VERSION "J35_Common"

NS_ :

BS_:

BU_: PCM UNKNOWN

BO_ 316 PCM_0x13C: 8 PCM
 SG_ TORQUE_ESTIMATE : 7|16@0- (1,0) [-32768|32767] "raw"  UNKNOWN
 SG_ TORQUE_TARGET : 23|16@0- (1,0) [-32768|32767] "raw"  UNKNOWN
 SG_ ACCELERATOR_REQUEST : 32|8@1+ (0.39215686274509803,0) [0|100] "%"  UNKNOWN
 SG_ TORQUE_STATE : 40|2@1+ (1,0) [0|3] ""  UNKNOWN
 SG_ RSVD_1 : 42|2@1+ (1,0) [0|3] ""  UNKNOWN
 SG_ UNKNOWN_1 : 44|1@1+ (1,0) [0|1] ""  UNKNOWN
 SG_ FRAME_1AA_WINDOW_LATCH : 45|1@1+ (1,0) [0|1] ""  UNKNOWN
 SG_ START_PHASE_LATCH : 46|1@1+ (1,0) [0|1] ""  UNKNOWN
 SG_ DTC_STATUS_7_LATCH : 47|1@1+ (1,0) [0|1] ""  UNKNOWN
 SG_ RSVD_3 : 48|2@1+ (1,0) [0|3] ""  UNKNOWN
 SG_ CLUTCH_ENGAGEMENT_INFORMATION_CRUISE_CONTROL : 50|1@1+ (1,0) [0|1] ""  UNKNOWN
 SG_ CONTROL_GUARD : 51|1@1+ (1,0) [0|1] ""  UNKNOWN
 SG_ RSVD_4 : 52|4@1+ (1,0) [0|15] ""  UNKNOWN
 SG_ CHECKSUM : 56|4@1+ (1,0) [0|15] ""  UNKNOWN
 SG_ COUNTER : 60|2@1+ (1,0) [0|3] ""  UNKNOWN
 SG_ RSVD_5 : 62|1@1+ (1,0) [0|1] ""  UNKNOWN
 SG_ FRAME_1AA_INVALID_OR_FALLBACK_STATE_TBD : 63|1@1+ (1,0) [0|1] ""  UNKNOWN
VAL_ 316 CLUTCH_ENGAGEMENT_INFORMATION_CRUISE_CONTROL 0 "ON" 1 "OFF" ;
VAL_ 316 TORQUE_STATE 0 "NORMAL" 1 "VSA_CONTROL_CANDIDATE" 2 "FUEL_CUT" 3 "UNKNOWN" ;

CM_ SG_ 316 CLUTCH_ENGAGEMENT_INFORMATION_CRUISE_CONTROL "CANFI: Clutch Engagement Information (Cruise Control)";
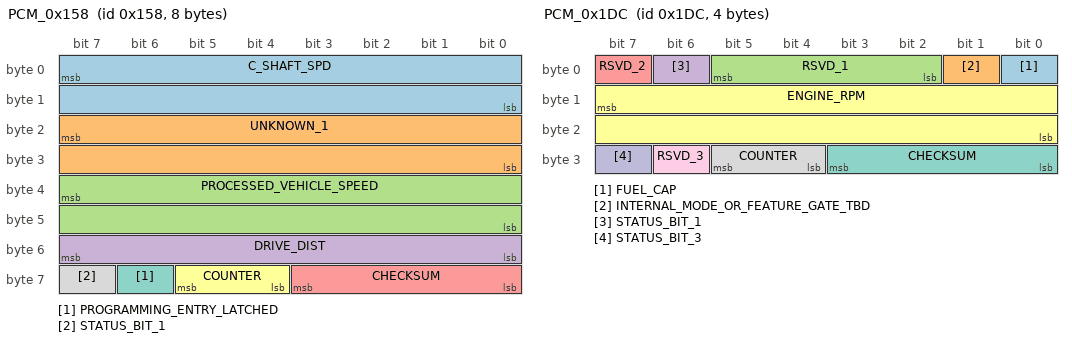
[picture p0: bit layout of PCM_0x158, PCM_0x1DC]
BO_ 344 PCM_0x158: 8 PCM
 SG_ C_SHAFT_SPD : 7|16@0+ (0.01,0) [0|655.35] ""  UNKNOWN
 SG_ UNKNOWN_1 : 23|16@0+ (1,0) [0|65535] "raw"  UNKNOWN
 SG_ PROCESSED_VEHICLE_SPEED : 39|16@0+ (0.01,0) [0|655.35] ""  UNKNOWN
 SG_ DRIVE_DIST : 48|8@1+ (1,0) [0|255] "raw"  UNKNOWN
 SG_ CHECKSUM : 56|4@1+ (1,0) [0|15] ""  UNKNOWN
 SG_ COUNTER : 60|2@1+ (1,0) [0|3] ""  UNKNOWN
 SG_ PROGRAMMING_ENTRY_LATCHED : 62|1@1+ (1,0) [0|1] ""  UNKNOWN
 SG_ STATUS_BIT_1 : 63|1@1+ (1,0) [0|1] ""  UNKNOWN

CM_ SG_ 344 DRIVE_DIST "CANFI: Drive Dist";
BO_ 380 PCM_0x17C: 8 PCM
 SG_ ACCELERATOR_PEDAL_POSITION : 0|8@1+ (0.39215686274509803,0) [0|100] "%"  UNKNOWN
 SG_ THROTTLE_ABOVE_IDLE : 8|8@1+ (0.4,0) [0|102] "deg"  UNKNOWN
 SG_ ENGINE_SPEED : 23|16@0+ (1,0) [0|65535] "rpm"  UNKNOWN
 SG_ BRAKE_SWITCH : 32|1@1+ (1,0) [0|1] ""  UNKNOWN
 SG_ CRUISE_CANCEL_EVENT : 33|1@1+ (1,0) [0|1] ""  UNKNOWN
 SG_ CRUISE_FAULT_SPEED_INHIBIT : 34|1@1+ (1,0) [0|1] ""  UNKNOWN
 SG_ CRUISE_ENGAGED : 35|1@1+ (1,0) [0|1] ""  UNKNOWN
 SG_ MIL : 36|1@1+ (1,0) [0|1] ""  UNKNOWN
 SG_ MIL_STATUS : 37|1@1+ (1,0) [0|1] ""  UNKNOWN
 SG_ CRUISE_INDICATOR : 38|1@1+ (1,0) [0|1] ""  UNKNOWN
 SG_ GAS_PEDAL_PRESSED : 39|1@1+ (1,0) [0|1] ""  UNKNOWN
 SG_ RSVD_1 : 40|2@1+ (1,0) [0|3] ""  UNKNOWN
 SG_ ACCEL_PEDAL_FAULT : 42|1@1+ (1,0) [0|1] ""  UNKNOWN
 SG_ RSVD_2 : 43|5@1+ (1,0) [0|31] ""  UNKNOWN
 SG_ RSVD_3 : 48|5@1+ (1,0) [0|31] ""  UNKNOWN
 SG_ CRUISE_BRAKE_SW_IDLE_STOP_SW : 53|1@1+ (1,0) [0|1] ""  UNKNOWN
 SG_ CRUISE_TRANS_REQUEST_WIRE : 54|2@1+ (1,0) [0|3] ""  UNKNOWN
 SG_ CHECKSUM : 56|4@1+ (1,0) [0|15] ""  UNKNOWN
 SG_ COUNTER : 60|2@1+ (1,0) [0|3] ""  UNKNOWN
 SG_ RSVD_4 : 62|1@1+ (1,0) [0|1] ""  UNKNOWN
 SG_ DTC_GROUP_WARNING_REQUESTED : 63|1@1+ (1,0) [0|1] ""  UNKNOWN
VAL_ 380 CRUISE_BRAKE_SW_IDLE_STOP_SW 0 "CLOSE" 1 "OPEN" ;
VAL_ 380 CRUISE_INDICATOR 0 "OFF" 1 "ON" ;
VAL_ 380 MIL_STATUS 0 "OFF" 1 "ON" ;
VAL_ 380 MIL 0 "OFF" 1 "ON" ;
VAL_ 380 BRAKE_SWITCH 0 "OFF" 1 "ON" ;

CM_ SG_ 380 ENGINE_SPEED "CANFI: Engine Speed";
CM_ SG_ 380 BRAKE_SWITCH "CANFI: Brake Switch";
CM_ SG_ 380 MIL "CANFI: MIL";
CM_ SG_ 380 MIL_STATUS "CANFI: MIL Status";
CM_ SG_ 380 CRUISE_INDICATOR "CANFI: Cruise Indicator";
CM_ SG_ 380 CRUISE_BRAKE_SW_IDLE_STOP_SW "CANFI: Cruise Brake Sw/Idle Stop Sw";
BO_ 476 PCM_0x1DC: 4 PCM
 SG_ FUEL_CAP : 0|1@1+ (1,0) [0|1] ""  UNKNOWN
 SG_ INTERNAL_MODE_OR_FEATURE_GATE_TBD : 1|1@1+ (1,0) [0|1] ""  UNKNOWN
 SG_ RSVD_1 : 2|4@1+ (1,0) [0|15] ""  UNKNOWN
 SG_ STATUS_BIT_1 : 6|1@1+ (1,0) [0|1] ""  UNKNOWN
 SG_ RSVD_2 : 7|1@1+ (1,0) [0|1] ""  UNKNOWN
 SG_ ENGINE_RPM : 15|16@0+ (1,0) [0|65535] "rpm"  UNKNOWN
 SG_ CHECKSUM : 24|4@1+ (1,0) [0|15] ""  UNKNOWN
 SG_ COUNTER : 28|2@1+ (1,0) [0|3] ""  UNKNOWN
 SG_ RSVD_3 : 30|1@1+ (1,0) [0|1] ""  UNKNOWN
 SG_ STATUS_BIT_3 : 31|1@1+ (1,0) [0|1] ""  UNKNOWN
VAL_ 476 FUEL_CAP 0 "CLOSE" 1 "OPEN" ;

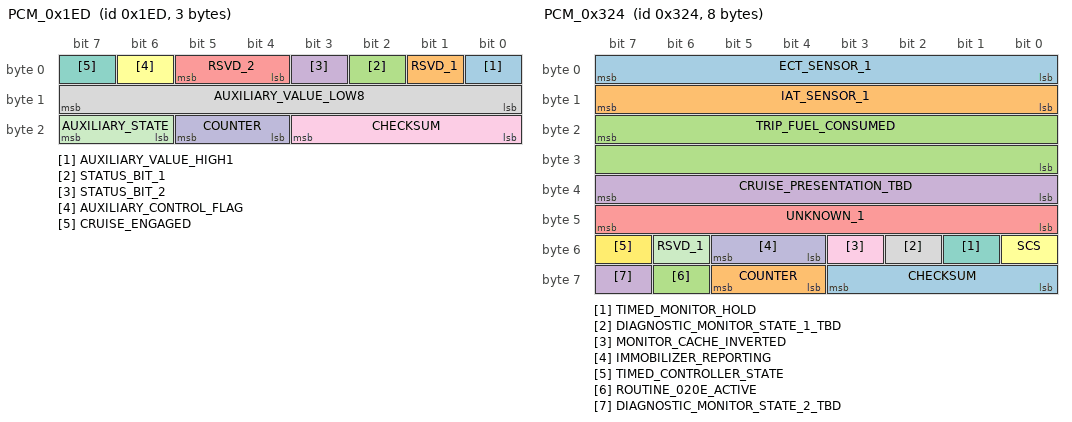
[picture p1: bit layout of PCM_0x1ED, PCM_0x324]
BO_ 493 PCM_0x1ED: 3 PCM
 SG_ AUXILIARY_VALUE_HIGH1 : 0|1@1+ (1,0) [0|1] ""  UNKNOWN
 SG_ RSVD_1 : 1|1@1+ (1,0) [0|1] ""  UNKNOWN
 SG_ STATUS_BIT_1 : 2|1@1+ (1,0) [0|1] ""  UNKNOWN
 SG_ STATUS_BIT_2 : 3|1@1+ (1,0) [0|1] ""  UNKNOWN
 SG_ RSVD_2 : 4|2@1+ (1,0) [0|3] ""  UNKNOWN
 SG_ AUXILIARY_CONTROL_FLAG : 6|1@1+ (1,0) [0|1] ""  UNKNOWN
 SG_ CRUISE_ENGAGED : 7|1@1+ (1,0) [0|1] ""  UNKNOWN
 SG_ AUXILIARY_VALUE_LOW8 : 8|8@1+ (1,0) [0|255] ""  UNKNOWN
 SG_ CHECKSUM : 16|4@1+ (1,0) [0|15] ""  UNKNOWN
 SG_ COUNTER : 20|2@1+ (1,0) [0|3] ""  UNKNOWN
 SG_ AUXILIARY_STATE : 22|2@1+ (1,0) [0|3] ""  UNKNOWN

BO_ 800 PCM_0x320: 8 PCM
 SG_ RSVD_1 : 0|6@1+ (1,0) [0|63] ""  UNKNOWN
 SG_ ENGINE_STATE_TBD : 6|2@1+ (1,0) [0|3] ""  UNKNOWN
 SG_ STATUS_BIT_1 : 8|1@1+ (1,0) [0|1] ""  UNKNOWN
 SG_ STATUS_BIT_2 : 9|1@1+ (1,0) [0|1] ""  UNKNOWN
 SG_ RSVD_2 : 10|4@1+ (1,0) [0|15] ""  UNKNOWN
 SG_ STATUS_BIT_3 : 14|1@1+ (1,0) [0|1] ""  UNKNOWN
 SG_ RSVD_3 : 15|1@1+ (1,0) [0|1] ""  UNKNOWN
 SG_ UNKNOWN_1 : 16|3@1+ (1,0) [0|7] ""  UNKNOWN
 SG_ UNKNOWN_4 : 19|3@1+ (1,0) [0|7] ""  UNKNOWN
 SG_ STATUS_BIT_4 : 22|1@1+ (1,0) [0|1] ""  UNKNOWN
 SG_ STATUS_BIT_9_TBD : 23|1@1+ (1,0) [0|1] ""  UNKNOWN
 SG_ RSVD_4 : 24|8@1+ (1,0) [0|255] ""  UNKNOWN
 SG_ RSVD_5 : 32|7@1+ (1,0) [0|127] ""  UNKNOWN
 SG_ STATUS_BIT_5 : 39|1@1+ (1,0) [0|1] ""  UNKNOWN
 SG_ UNKNOWN_2 : 40|3@1+ (1,0) [0|7] ""  UNKNOWN
 SG_ UNKNOWN_3 : 43|3@1+ (1,0) [0|7] ""  UNKNOWN
 SG_ UNKNOWN_5 : 46|2@1+ (1,0) [0|3] ""  UNKNOWN
 SG_ STATUS_BIT_6 : 48|1@1+ (1,0) [0|1] ""  UNKNOWN
 SG_ RSVD_6 : 49|2@1+ (1,0) [0|3] ""  UNKNOWN
 SG_ STATUS_BIT_7 : 51|1@1+ (1,0) [0|1] ""  UNKNOWN
 SG_ RSVD_7 : 52|4@1+ (1,0) [0|15] ""  UNKNOWN
 SG_ CHECKSUM : 56|4@1+ (1,0) [0|15] ""  UNKNOWN
 SG_ COUNTER : 60|2@1+ (1,0) [0|3] ""  UNKNOWN
 SG_ STATUS_BIT_8 : 62|1@1+ (1,0) [0|1] ""  UNKNOWN
 SG_ STATUS_BIT_9 : 63|1@1+ (1,0) [0|1] ""  UNKNOWN

BO_ 804 PCM_0x324: 8 PCM
 SG_ ECT_SENSOR_1 : 0|8@1+ (1,-40) [-40|215] "degC"  UNKNOWN
 SG_ IAT_SENSOR_1 : 8|8@1+ (1,-40) [-40|215] "degC"  UNKNOWN
 SG_ TRIP_FUEL_CONSUMED : 23|16@0+ (1,0) [0|65535] ""  UNKNOWN
 SG_ CRUISE_PRESENTATION_TBD : 32|8@1+ (1,0) [0|255] "raw"  UNKNOWN
 SG_ UNKNOWN_1 : 40|8@1- (1,0) [-128|127] "raw"  UNKNOWN
 SG_ SCS : 48|1@1+ (1,0) [0|1] ""  UNKNOWN
 SG_ TIMED_MONITOR_HOLD : 49|1@1+ (1,0) [0|1] ""  UNKNOWN
 SG_ DIAGNOSTIC_MONITOR_STATE_1_TBD : 50|1@1+ (1,0) [0|1] ""  UNKNOWN
 SG_ MONITOR_CACHE_INVERTED : 51|1@1+ (1,0) [0|1] ""  UNKNOWN
 SG_ IMMOBILIZER_REPORTING : 52|2@1+ (1,0) [0|3] ""  UNKNOWN
 SG_ RSVD_1 : 54|1@1+ (1,0) [0|1] ""  UNKNOWN
 SG_ TIMED_CONTROLLER_STATE : 55|1@1+ (1,0) [0|1] ""  UNKNOWN
 SG_ CHECKSUM : 56|4@1+ (1,0) [0|15] ""  UNKNOWN
 SG_ COUNTER : 60|2@1+ (1,0) [0|3] ""  UNKNOWN
 SG_ ROUTINE_020E_ACTIVE : 62|1@1+ (1,0) [0|1] ""  UNKNOWN
 SG_ DIAGNOSTIC_MONITOR_STATE_2_TBD : 63|1@1+ (1,0) [0|1] ""  UNKNOWN
VAL_ 804 IMMOBILIZER_REPORTING 0 "COMPLETE_ACCEPTED" 1 "INCOMPLETE" 2 "COMPLETE_NOT_ACCEPTED" ;
VAL_ 804 SCS 0 "OPEN" 1 "SHORT" ;
VAL_ 804 IAT_SENSOR_1 255 "INVALID" ;
VAL_ 804 ECT_SENSOR_1 255 "INVALID" ;

CM_ SG_ 804 SCS "CANFI: SCS";
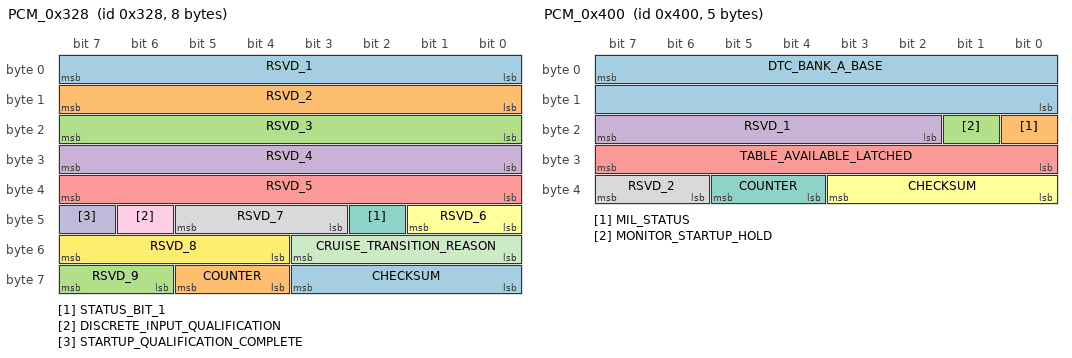
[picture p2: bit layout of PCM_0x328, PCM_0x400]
BO_ 808 PCM_0x328: 8 PCM
 SG_ RSVD_1 : 0|8@1+ (1,0) [0|255] ""  UNKNOWN
 SG_ RSVD_2 : 8|8@1+ (1,0) [0|255] ""  UNKNOWN
 SG_ RSVD_3 : 16|8@1+ (1,0) [0|255] ""  UNKNOWN
 SG_ RSVD_4 : 24|8@1+ (1,0) [0|255] ""  UNKNOWN
 SG_ RSVD_5 : 32|8@1+ (1,0) [0|255] ""  UNKNOWN
 SG_ RSVD_6 : 40|2@1+ (1,0) [0|3] ""  UNKNOWN
 SG_ STATUS_BIT_1 : 42|1@1+ (1,0) [0|1] ""  UNKNOWN
 SG_ RSVD_7 : 43|3@1+ (1,0) [0|7] ""  UNKNOWN
 SG_ DISCRETE_INPUT_QUALIFICATION : 46|1@1+ (1,0) [0|1] ""  UNKNOWN
 SG_ STARTUP_QUALIFICATION_COMPLETE : 47|1@1+ (1,0) [0|1] ""  UNKNOWN
 SG_ CRUISE_TRANSITION_REASON : 48|4@1+ (1,0) [0|15] ""  UNKNOWN
 SG_ RSVD_8 : 52|4@1+ (1,0) [0|15] ""  UNKNOWN
 SG_ CHECKSUM : 56|4@1+ (1,0) [0|15] ""  UNKNOWN
 SG_ COUNTER : 60|2@1+ (1,0) [0|3] ""  UNKNOWN
 SG_ RSVD_9 : 62|2@1+ (1,0) [0|3] ""  UNKNOWN

BO_ 1024 PCM_0x400: 5 PCM
 SG_ DTC_BANK_A_BASE : 7|16@0+ (1,0) [0|65535] ""  UNKNOWN
 SG_ MIL_STATUS : 16|1@1+ (1,0) [0|1] ""  UNKNOWN
 SG_ MONITOR_STARTUP_HOLD : 17|1@1+ (1,0) [0|1] ""  UNKNOWN
 SG_ RSVD_1 : 18|6@1+ (1,0) [0|63] ""  UNKNOWN
 SG_ TABLE_AVAILABLE_LATCHED : 24|8@1+ (1,0) [0|255] ""  UNKNOWN
 SG_ CHECKSUM : 32|4@1+ (1,0) [0|15] ""  UNKNOWN
 SG_ COUNTER : 36|2@1+ (1,0) [0|3] ""  UNKNOWN
 SG_ RSVD_2 : 38|2@1+ (1,0) [0|3] ""  UNKNOWN
VAL_ 1024 MIL_STATUS 0 "OFF" 1 "ON" ;

CM_ SG_ 1024 MIL_STATUS "CANFI: MIL Status";
BO_ 1036 PCM_0x40C: 8 PCM
 SG_ MULTIPLEX_PAGE M : 0|4@1+ (1,0) [0|15] ""  UNKNOWN
 SG_ MULTIPLEX_GROUP : 4|2@1+ (1,0) [0|3] ""  UNKNOWN
 SG_ DIAGNOSTIC_EVENT_STATE : 6|2@1+ (1,0) [0|3] ""  UNKNOWN
 SG_ RSVD_1 m0 : 8|8@1+ (1,0) [0|255] ""  UNKNOWN
 SG_ P01_VIN_CHARACTER_1_B1 m1 : 8|8@1+ (1,0) [0|255] ""  UNKNOWN
 SG_ P02_VIN_CHARACTER_7_B1 m2 : 8|8@1+ (1,0) [0|255] ""  UNKNOWN
 SG_ P03_VIN_CHARACTER_13_B1 m3 : 8|8@1+ (1,0) [0|255] ""  UNKNOWN
 SG_ P04_VARIANT_CONFIG_BYTE_1_B1 m4 : 8|8@1+ (1,0) [0|255] ""  UNKNOWN
 SG_ P05_ENGINE_SPEED m5 : 15|16@0+ (0.25,0) [0|16383.75] "rpm"  UNKNOWN
 SG_ P06_IAT_SENSOR_VOLTAGE_B1 m6 : 8|8@1+ (0.0196078431372549,0) [0|5] "V"  UNKNOWN
 SG_ P07_VEHICLE_SPEED_B1 m7 : 8|8@1+ (1,0) [0|255] "km/h"  UNKNOWN
 SG_ P08_APP_SENSOR m8 : 15|16@0+ (0.005,0) [0|327.675] "%"  UNKNOWN
 SG_ P09_TARGET_TH_VLV m9 : 15|16@0+ (0.005,0) [0|327.675] "deg"  UNKNOWN
 SG_ P0A_AF_SENSOR_B1 m10 : 15|16@0+ (1,0) [0|65535] ""  UNKNOWN
 SG_ UNKNOWN_1 m11 : 8|8@1+ (1,0) [0|255] ""  UNKNOWN
 SG_ P0C_AF_FB_ST_FUEL_TRIM_B2 m12 : 8|8@1+ (0.0078125,0) [0|1.9921875] "ratio"  UNKNOWN
 SG_ P0D_EGR_VALVE_POSITION_SENSOR_EGR_VLS m13 : 8|8@1+ (1,0) [0|255] ""  UNKNOWN
 SG_ P0E_MASS_AIR_FLOW m14 : 15|16@0+ (0.01,0) [0|655.35] "g/s"  UNKNOWN
 SG_ P0F_FUEL_TANK_LEVEL_INPUT_B1 m15 : 8|8@1+ (0.39215686274509803,0) [0|100] "%"  UNKNOWN
 SG_ P00_DIAGNOSTIC_EVENT_CACHE_WORD m0 : 23|16@0+ (1,0) [0|65535] ""  UNKNOWN
 SG_ P01_VIN_CHARACTER_2_B2 m1 : 16|8@1+ (1,0) [0|255] ""  UNKNOWN
 SG_ P02_VIN_CHARACTER_8_B2 m2 : 16|8@1+ (1,0) [0|255] ""  UNKNOWN
 SG_ P03_VIN_CHARACTER_14_B2 m3 : 16|8@1+ (1,0) [0|255] ""  UNKNOWN
 SG_ P04_VARIANT_CONFIG_BYTE_2_B2 m4 : 16|8@1+ (1,0) [0|255] ""  UNKNOWN
 SG_ P06_INTAKE_AIR_TEMPERATURE_B2 m6 : 16|8@1+ (1,-40) [-40|215] "degC"  UNKNOWN
 SG_ P07_CALCULATED_ENGINE_LOAD_B2 m7 : 16|8@1+ (0.39215686274509803,0) [0|100] "%"  UNKNOWN
 SG_ P0B_HO2S_S2_B1 m11 : 16|8@1+ (0.0196078431372549,0) [0|5] "V"  UNKNOWN
 SG_ P0C_AF_FB_AVE_LT_FUEL_TRIM_B2 m12 : 16|8@1+ (0.0078125,0) [0|1.9921875] "ratio"  UNKNOWN
 SG_ RSVD_2 m13 : 16|8@1+ (1,0) [0|255] ""  UNKNOWN
 SG_ RSVD_3 m15 : 16|8@1+ (1,0) [0|255] ""  UNKNOWN
 SG_ P01_VIN_CHARACTER_3_B3 m1 : 24|8@1+ (1,0) [0|255] ""  UNKNOWN
 SG_ P02_VIN_CHARACTER_9_B3 m2 : 24|8@1+ (1,0) [0|255] ""  UNKNOWN
 SG_ P03_VIN_CHARACTER_15_B3 m3 : 24|8@1+ (1,0) [0|255] ""  UNKNOWN
 SG_ P04_VARIANT_CONFIG_BYTE_3_B3 m4 : 24|8@1+ (1,0) [0|255] ""  UNKNOWN
 SG_ P05_THROTTLE_POSITION_B3 m5 : 24|8@1+ (0.39215686274509803,0) [0|100] "%"  UNKNOWN
 SG_ P06_MAP_SENSOR_VOLTAGE_B3 m6 : 24|8@1+ (0.0196078431372549,0) [0|5] "V"  UNKNOWN
 SG_ P07_SPARK_ADVANCE m7 : 24|8@1+ (0.5,-64) [-64|63.5] "deg"  UNKNOWN
 SG_ P08_TP_SENSOR_1 m8 : 24|8@1+ (0.0196078431372549,0) [0|5] "V"  UNKNOWN
 SG_ UNKNOWN_2 m9 : 24|8@1+ (1,0) [0|255] ""  UNKNOWN
 SG_ P0A_AF_LAMBDA_B1 m10 : 31|16@0+ (3.0517578125e-05,0) [0|1.999969482421875] "ratio"  UNKNOWN
 SG_ P0B_AF_SENSOR_B2 m11 : 31|16@0+ (1,0) [0|65535] ""  UNKNOWN
 SG_ UNKNOWN_3 m12 : 24|8@1+ (1,0) [0|255] ""  UNKNOWN
 SG_ RSVD_4 m13 : 24|8@1+ (1,0) [0|255] ""  UNKNOWN
 SG_ RSVD_5 m14 : 24|8@1+ (1,0) [0|255] ""  UNKNOWN
 SG_ RSVD_6 m15 : 24|8@1+ (1,0) [0|255] ""  UNKNOWN
 SG_ UNKNOWN_4 m0 : 32|8@1+ (1,0) [0|255] ""  UNKNOWN
 SG_ P01_VIN_CHARACTER_4_B4 m1 : 32|8@1+ (1,0) [0|255] ""  UNKNOWN
 SG_ P02_VIN_CHARACTER_10_B4 m2 : 32|8@1+ (1,0) [0|255] ""  UNKNOWN
 SG_ P03_VIN_CHARACTER_16_B4 m3 : 32|8@1+ (1,0) [0|255] ""  UNKNOWN
 SG_ P04_VARIANT_CONFIG_BYTE_4_B4 m4 : 32|8@1+ (1,0) [0|255] ""  UNKNOWN
 SG_ P05_RELATIVE_THROTTLE_POSITION_B4 m5 : 32|8@1+ (0.39215686274509803,0) [0|100] "%"  UNKNOWN
 SG_ P06_MANIFOLD_ABSOLUTE_PRESSURE_B4 m6 : 32|8@1+ (1,0) [0|255] "kPa"  UNKNOWN
 SG_ P07_CONTROL_MODULE_VOLTAGE_DECIVOLT m7 : 32|8@1+ (0.1,0) [0|25.5] "V"  UNKNOWN
 SG_ P08_TP_SENSOR_2 m8 : 32|8@1+ (0.0196078431372549,0) [0|5] "V"  UNKNOWN
 SG_ UNKNOWN_5 m9 : 32|8@1+ (1,0) [0|255] ""  UNKNOWN
 SG_ P0C_HO2S_S2_B2 m12 : 32|8@1+ (0.0196078431372549,0) [0|5] "V"  UNKNOWN
 SG_ P0D_MAF_SENSOR m13 : 32|8@1+ (0.0196078431372549,0) [0|5] "V"  UNKNOWN
 SG_ P0E_RUNTIME_SINCE_ENGINE_START m14 : 39|16@0+ (1,0) [0|65535] "s"  UNKNOWN
 SG_ RSVD_7 m15 : 32|8@1+ (1,0) [0|255] ""  UNKNOWN
 SG_ RSVD_8 m0 : 40|8@1+ (1,0) [0|255] ""  UNKNOWN
 SG_ P01_VIN_CHARACTER_5_B5 m1 : 40|8@1+ (1,0) [0|255] ""  UNKNOWN
 SG_ P02_VIN_CHARACTER_11_B5 m2 : 40|8@1+ (1,0) [0|255] ""  UNKNOWN
 SG_ P03_VIN_CHARACTER_17_B5 m3 : 40|8@1+ (1,0) [0|255] ""  UNKNOWN
 SG_ P04_VARIANT_CONFIG_BYTE_5_B5 m4 : 40|8@1+ (1,0) [0|255] ""  UNKNOWN
 SG_ P05_ECT_SENSOR_VOLTAGE_B5 m5 : 40|8@1+ (0.0196078431372549,0) [0|5] "V"  UNKNOWN
 SG_ P06_BARO_SENSOR_VOLTAGE_B5 m6 : 40|8@1+ (0.0196078431372549,0) [0|5] "V"  UNKNOWN
 SG_ P07_APP_SENSOR_A_VOLTAGE_B5 m7 : 40|8@1+ (0.0196078431372549,0) [0|5] "V"  UNKNOWN
 SG_ P08_THROTTLE_VLV m8 : 47|16@0+ (0.005,0) [0|327.675] "deg"  UNKNOWN
 SG_ P09_IDLE_TARGET_TH m9 : 47|16@0+ (0.005,0) [0|327.675] "deg"  UNKNOWN
 SG_ P0A_SHORT_TERM_FUEL_TRIM_BANK_1_B5 m10 : 40|8@1+ (0.78125,-100) [-100|99.21875] "%"  UNKNOWN
 SG_ P0B_AF_LAMBDA_B2 m11 : 47|16@0+ (3.0517578125e-05,0) [0|1.999969482421875] "ratio"  UNKNOWN
 SG_ P0C_F_INJECTOR m12 : 47|16@0+ (0.004,0) [0|262.14] "ms"  UNKNOWN
 SG_ RSVD_9 m13 : 40|8@1+ (1,0) [0|255] ""  UNKNOWN
 SG_ RSVD_10 m15 : 40|8@1+ (1,0) [0|255] ""  UNKNOWN
 SG_ RSVD_11 m0 : 48|8@1+ (1,0) [0|255] ""  UNKNOWN
 SG_ P01_VIN_CHARACTER_6_B6 m1 : 48|8@1+ (1,0) [0|255] ""  UNKNOWN
 SG_ P02_VIN_CHARACTER_12_B6 m2 : 48|8@1+ (1,0) [0|255] ""  UNKNOWN
 SG_ UNKNOWN_6 m3 : 48|8@1+ (1,0) [0|255] ""  UNKNOWN
 SG_ RSVD_12 m4 : 48|8@1+ (1,0) [0|255] ""  UNKNOWN
 SG_ P05_ENGINE_COOLANT_TEMPERATURE_B6 m5 : 48|8@1+ (1,-40) [-40|215] "degC"  UNKNOWN
 SG_ P06_BAROMETRIC_PRESSURE_B6 m6 : 48|8@1+ (1,0) [0|255] "kPa"  UNKNOWN
 SG_ P07_APP_SENSOR_B_VOLTAGE_B6 m7 : 48|8@1+ (0.0196078431372549,0) [0|5] "V"  UNKNOWN
 SG_ P0A_LONG_TERM_FUEL_TRIM_BANK_1_B6 m10 : 48|8@1+ (0.78125,-100) [-100|99.21875] "%"  UNKNOWN
 SG_ RSVD_13 m13 : 48|8@1+ (1,0) [0|255] ""  UNKNOWN
 SG_ P0E_COMMANDED_EVAPORATIVE_PURGE_B6 m14 : 48|8@1+ (0.39215686274509803,0) [0|100] "%"  UNKNOWN
 SG_ RSVD_14 m15 : 48|8@1+ (1,0) [0|255] ""  UNKNOWN
 SG_ CHECKSUM : 56|4@1+ (1,0) [0|15] ""  UNKNOWN
 SG_ COUNTER : 60|2@1+ (1,0) [0|3] ""  UNKNOWN
 SG_ DIAGNOSTIC_STATUS_FLAG_6 m0 : 62|1@1+ (1,0) [0|1] ""  UNKNOWN
 SG_ DIAGNOSTIC_STATUS_FLAG_7 m0 : 63|1@1+ (1,0) [0|1] ""  UNKNOWN
 SG_ RSVD_15 m5 : 62|2@1+ (1,0) [0|3] ""  UNKNOWN
SG_MUL_VAL_ 1036 RSVD_1 MULTIPLEX_PAGE 0-0;
SG_MUL_VAL_ 1036 P01_VIN_CHARACTER_1_B1 MULTIPLEX_PAGE 1-1;
SG_MUL_VAL_ 1036 P02_VIN_CHARACTER_7_B1 MULTIPLEX_PAGE 2-2;
SG_MUL_VAL_ 1036 P03_VIN_CHARACTER_13_B1 MULTIPLEX_PAGE 3-3;
SG_MUL_VAL_ 1036 P04_VARIANT_CONFIG_BYTE_1_B1 MULTIPLEX_PAGE 4-4;
SG_MUL_VAL_ 1036 P05_ENGINE_SPEED MULTIPLEX_PAGE 5-5;
SG_MUL_VAL_ 1036 P06_IAT_SENSOR_VOLTAGE_B1 MULTIPLEX_PAGE 6-6;
SG_MUL_VAL_ 1036 P07_VEHICLE_SPEED_B1 MULTIPLEX_PAGE 7-7;
SG_MUL_VAL_ 1036 P08_APP_SENSOR MULTIPLEX_PAGE 8-8;
SG_MUL_VAL_ 1036 P09_TARGET_TH_VLV MULTIPLEX_PAGE 9-9;
SG_MUL_VAL_ 1036 P0A_AF_SENSOR_B1 MULTIPLEX_PAGE 10-10;
SG_MUL_VAL_ 1036 UNKNOWN_1 MULTIPLEX_PAGE 11-11;
SG_MUL_VAL_ 1036 P0C_AF_FB_ST_FUEL_TRIM_B2 MULTIPLEX_PAGE 12-12;
SG_MUL_VAL_ 1036 P0D_EGR_VALVE_POSITION_SENSOR_EGR_VLS MULTIPLEX_PAGE 13-13;
SG_MUL_VAL_ 1036 P0E_MASS_AIR_FLOW MULTIPLEX_PAGE 14-14;
SG_MUL_VAL_ 1036 P0F_FUEL_TANK_LEVEL_INPUT_B1 MULTIPLEX_PAGE 15-15;
SG_MUL_VAL_ 1036 P00_DIAGNOSTIC_EVENT_CACHE_WORD MULTIPLEX_PAGE 0-0;
SG_MUL_VAL_ 1036 P01_VIN_CHARACTER_2_B2 MULTIPLEX_PAGE 1-1;
SG_MUL_VAL_ 1036 P02_VIN_CHARACTER_8_B2 MULTIPLEX_PAGE 2-2;
SG_MUL_VAL_ 1036 P03_VIN_CHARACTER_14_B2 MULTIPLEX_PAGE 3-3;
SG_MUL_VAL_ 1036 P04_VARIANT_CONFIG_BYTE_2_B2 MULTIPLEX_PAGE 4-4;
SG_MUL_VAL_ 1036 P06_INTAKE_AIR_TEMPERATURE_B2 MULTIPLEX_PAGE 6-6;
SG_MUL_VAL_ 1036 P07_CALCULATED_ENGINE_LOAD_B2 MULTIPLEX_PAGE 7-7;
SG_MUL_VAL_ 1036 P0B_HO2S_S2_B1 MULTIPLEX_PAGE 11-11;
SG_MUL_VAL_ 1036 P0C_AF_FB_AVE_LT_FUEL_TRIM_B2 MULTIPLEX_PAGE 12-12;
SG_MUL_VAL_ 1036 RSVD_2 MULTIPLEX_PAGE 13-13;
SG_MUL_VAL_ 1036 RSVD_3 MULTIPLEX_PAGE 15-15;
SG_MUL_VAL_ 1036 P01_VIN_CHARACTER_3_B3 MULTIPLEX_PAGE 1-1;
SG_MUL_VAL_ 1036 P02_VIN_CHARACTER_9_B3 MULTIPLEX_PAGE 2-2;
SG_MUL_VAL_ 1036 P03_VIN_CHARACTER_15_B3 MULTIPLEX_PAGE 3-3;
SG_MUL_VAL_ 1036 P04_VARIANT_CONFIG_BYTE_3_B3 MULTIPLEX_PAGE 4-4;
SG_MUL_VAL_ 1036 P05_THROTTLE_POSITION_B3 MULTIPLEX_PAGE 5-5;
SG_MUL_VAL_ 1036 P06_MAP_SENSOR_VOLTAGE_B3 MULTIPLEX_PAGE 6-6;
SG_MUL_VAL_ 1036 P07_SPARK_ADVANCE MULTIPLEX_PAGE 7-7;
SG_MUL_VAL_ 1036 P08_TP_SENSOR_1 MULTIPLEX_PAGE 8-8;
SG_MUL_VAL_ 1036 UNKNOWN_2 MULTIPLEX_PAGE 9-9;
SG_MUL_VAL_ 1036 P0A_AF_LAMBDA_B1 MULTIPLEX_PAGE 10-10;
SG_MUL_VAL_ 1036 P0B_AF_SENSOR_B2 MULTIPLEX_PAGE 11-11;
SG_MUL_VAL_ 1036 UNKNOWN_3 MULTIPLEX_PAGE 12-12;
SG_MUL_VAL_ 1036 RSVD_4 MULTIPLEX_PAGE 13-13;
SG_MUL_VAL_ 1036 RSVD_5 MULTIPLEX_PAGE 14-14;
SG_MUL_VAL_ 1036 RSVD_6 MULTIPLEX_PAGE 15-15;
SG_MUL_VAL_ 1036 UNKNOWN_4 MULTIPLEX_PAGE 0-0;
SG_MUL_VAL_ 1036 P01_VIN_CHARACTER_4_B4 MULTIPLEX_PAGE 1-1;
SG_MUL_VAL_ 1036 P02_VIN_CHARACTER_10_B4 MULTIPLEX_PAGE 2-2;
SG_MUL_VAL_ 1036 P03_VIN_CHARACTER_16_B4 MULTIPLEX_PAGE 3-3;
SG_MUL_VAL_ 1036 P04_VARIANT_CONFIG_BYTE_4_B4 MULTIPLEX_PAGE 4-4;
SG_MUL_VAL_ 1036 P05_RELATIVE_THROTTLE_POSITION_B4 MULTIPLEX_PAGE 5-5;
SG_MUL_VAL_ 1036 P06_MANIFOLD_ABSOLUTE_PRESSURE_B4 MULTIPLEX_PAGE 6-6;
SG_MUL_VAL_ 1036 P07_CONTROL_MODULE_VOLTAGE_DECIVOLT MULTIPLEX_PAGE 7-7;
SG_MUL_VAL_ 1036 P08_TP_SENSOR_2 MULTIPLEX_PAGE 8-8;
SG_MUL_VAL_ 1036 UNKNOWN_5 MULTIPLEX_PAGE 9-9;
SG_MUL_VAL_ 1036 P0C_HO2S_S2_B2 MULTIPLEX_PAGE 12-12;
SG_MUL_VAL_ 1036 P0D_MAF_SENSOR MULTIPLEX_PAGE 13-13;
SG_MUL_VAL_ 1036 P0E_RUNTIME_SINCE_ENGINE_START MULTIPLEX_PAGE 14-14;
SG_MUL_VAL_ 1036 RSVD_7 MULTIPLEX_PAGE 15-15;
SG_MUL_VAL_ 1036 RSVD_8 MULTIPLEX_PAGE 0-0;
SG_MUL_VAL_ 1036 P01_VIN_CHARACTER_5_B5 MULTIPLEX_PAGE 1-1;
SG_MUL_VAL_ 1036 P02_VIN_CHARACTER_11_B5 MULTIPLEX_PAGE 2-2;
SG_MUL_VAL_ 1036 P03_VIN_CHARACTER_17_B5 MULTIPLEX_PAGE 3-3;
SG_MUL_VAL_ 1036 P04_VARIANT_CONFIG_BYTE_5_B5 MULTIPLEX_PAGE 4-4;
SG_MUL_VAL_ 1036 P05_ECT_SENSOR_VOLTAGE_B5 MULTIPLEX_PAGE 5-5;
SG_MUL_VAL_ 1036 P06_BARO_SENSOR_VOLTAGE_B5 MULTIPLEX_PAGE 6-6;
SG_MUL_VAL_ 1036 P07_APP_SENSOR_A_VOLTAGE_B5 MULTIPLEX_PAGE 7-7;
SG_MUL_VAL_ 1036 P08_THROTTLE_VLV MULTIPLEX_PAGE 8-8;
SG_MUL_VAL_ 1036 P09_IDLE_TARGET_TH MULTIPLEX_PAGE 9-9;
SG_MUL_VAL_ 1036 P0A_SHORT_TERM_FUEL_TRIM_BANK_1_B5 MULTIPLEX_PAGE 10-10;
SG_MUL_VAL_ 1036 P0B_AF_LAMBDA_B2 MULTIPLEX_PAGE 11-11;
SG_MUL_VAL_ 1036 P0C_F_INJECTOR MULTIPLEX_PAGE 12-12;
SG_MUL_VAL_ 1036 RSVD_9 MULTIPLEX_PAGE 13-13;
SG_MUL_VAL_ 1036 RSVD_10 MULTIPLEX_PAGE 15-15;
SG_MUL_VAL_ 1036 RSVD_11 MULTIPLEX_PAGE 0-0;
SG_MUL_VAL_ 1036 P01_VIN_CHARACTER_6_B6 MULTIPLEX_PAGE 1-1;
SG_MUL_VAL_ 1036 P02_VIN_CHARACTER_12_B6 MULTIPLEX_PAGE 2-2;
SG_MUL_VAL_ 1036 UNKNOWN_6 MULTIPLEX_PAGE 3-3;
SG_MUL_VAL_ 1036 RSVD_12 MULTIPLEX_PAGE 4-4;
SG_MUL_VAL_ 1036 P05_ENGINE_COOLANT_TEMPERATURE_B6 MULTIPLEX_PAGE 5-5;
SG_MUL_VAL_ 1036 P06_BAROMETRIC_PRESSURE_B6 MULTIPLEX_PAGE 6-6;
SG_MUL_VAL_ 1036 P07_APP_SENSOR_B_VOLTAGE_B6 MULTIPLEX_PAGE 7-7;
SG_MUL_VAL_ 1036 P0A_LONG_TERM_FUEL_TRIM_BANK_1_B6 MULTIPLEX_PAGE 10-10;
SG_MUL_VAL_ 1036 RSVD_13 MULTIPLEX_PAGE 13-13;
SG_MUL_VAL_ 1036 P0E_COMMANDED_EVAPORATIVE_PURGE_B6 MULTIPLEX_PAGE 14-14;
SG_MUL_VAL_ 1036 RSVD_14 MULTIPLEX_PAGE 15-15;

SG_MUL_VAL_ 1036 DIAGNOSTIC_STATUS_FLAG_6 MULTIPLEX_PAGE 0-4;
SG_MUL_VAL_ 1036 DIAGNOSTIC_STATUS_FLAG_7 MULTIPLEX_PAGE 0-4;
SG_MUL_VAL_ 1036 RSVD_15 MULTIPLEX_PAGE 5-15;
BO_ 1108 PCM_0x454: 8 PCM
 SG_ RETAINED_MODEL_QUANTITY : 0|8@1+ (1,0) [0|255] ""  UNKNOWN
 SG_ BARO_DISPLAY : 8|8@1+ (1,0) [0|255] ""  UNKNOWN
 SG_ UNKNOWN_1 : 16|4@1+ (1,0) [0|15] ""  UNKNOWN
 SG_ BAROMETRIC_SENSOR_FAULT_AGGREGATE : 20|1@1+ (1,0) [0|1] ""  UNKNOWN
 SG_ SIGNED_STATE_BIT_5 : 21|1@1+ (1,0) [0|1] ""  UNKNOWN
 SG_ MODEL_HOLD_ACTIVE : 22|1@1+ (1,0) [0|1] ""  UNKNOWN
 SG_ STATUS_BIT_1 : 23|1@1+ (1,0) [0|1] ""  UNKNOWN
 SG_ SCALED_MODEL_QUANTITY : 31|16@0+ (1,0) [0|65535] ""  UNKNOWN
 SG_ RSVD_1 : 40|8@1+ (1,0) [0|255] ""  UNKNOWN
 SG_ ELECTRICAL_MONITOR_SECONDARY : 48|1@1+ (1,0) [0|1] ""  UNKNOWN
 SG_ STATUS_BIT_2 : 49|1@1+ (1,0) [0|1] ""  UNKNOWN
 SG_ STATUS_BIT_3 : 50|1@1+ (1,0) [0|1] ""  UNKNOWN
 SG_ ELECTRICAL_MONITOR_PRIMARY : 51|1@1+ (1,0) [0|1] ""  UNKNOWN
 SG_ RSVD_2 : 52|1@1+ (1,0) [0|1] ""  UNKNOWN
 SG_ RSVD_3 : 53|1@1+ (1,0) [0|1] ""  UNKNOWN
 SG_ RSVD_4 : 54|1@1+ (1,0) [0|1] ""  UNKNOWN
 SG_ MONITOR_HOLD : 55|1@1+ (1,0) [0|1] ""  UNKNOWN
 SG_ CHECKSUM : 56|4@1+ (1,0) [0|15] ""  UNKNOWN
 SG_ COUNTER : 60|2@1+ (1,0) [0|3] ""  UNKNOWN
 SG_ RSVD_5 : 62|2@1+ (1,0) [0|3] ""  UNKNOWN
